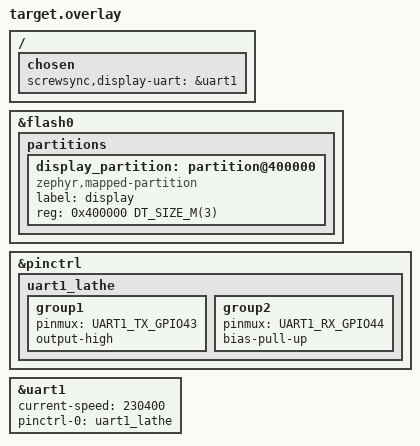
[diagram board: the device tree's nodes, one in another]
#include <zephyr/dt-bindings/pinctrl/esp32s3-pinctrl.h>

&flash0 {
	partitions {
		/* Stored display .tft (DisplayImage.cpp). */
		display_partition: partition@400000 {
			compatible = "zephyr,mapped-partition";
			label = "display";
			reg = <0x400000 DT_SIZE_M(3)>;
		};
	};
};

&pinctrl {
	uart1_lathe: uart1_lathe {
		group1 {
			pinmux = <UART1_TX_GPIO43>;
			output-high;
		};

		group2 {
			pinmux = <UART1_RX_GPIO44>;
			bias-pull-up;
		};
	};
};

&uart1 {
	status = "okay";
	current-speed = <230400>;
	pinctrl-0 = <&uart1_lathe>;
	pinctrl-names = "default";
};

/ {
	chosen {
		screwsync,display-uart = &uart1;
	};
};
